# ESP32-S31 register map
Vendor: ESPRESSIF SYSTEMS (SHANGHAI) CO., LTD.; Series: ESP32 S-Series; File version: 1
CPU: RV32IMAFC r0p0, little endian, no MPU, FPU, 0 interrupt priority bits
Address unit: 32 bits
Registers are 32-bit, read-write, reset 0x0 unless marked. A register's access mark holds for its fields unless they carry their own. Offsets are from the block's base; [hi:lo] are bit positions; {n}, {i} and the like mark numbered series.

## ECDSA — ECDSA (Elliptic Curve Digital Signature Algorithm) Accelerator
Base 0x2050E000
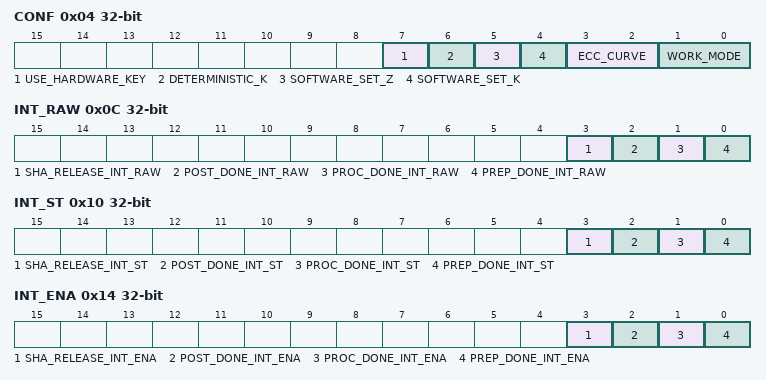
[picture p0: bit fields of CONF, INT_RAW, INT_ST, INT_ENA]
0x04 CONF — ECDSA configure register
  [7] USE_HARDWARE_KEY — Configures the ECDSA use software key or hardware key.\\ 0: Software key. \\ 1: Hardware key. \\
  [6] DETERMINISTIC_K — The source of hardware generated k. 0: k is generated by TRNG. 1: k is generated by deterministic derivation algorithm.
  [5] SOFTWARE_SET_Z — The source of z select bit. 0: z is generated from SHA result. 1: z is written by software.
  [4] SOFTWARE_SET_K — The source of k select bit. 0: k is automatically generated by hardware. 1: k is written by software.
  [3:2] ECC_CURVE — The ecc curve select bit of ECDSA Accelerator. 0: P-192. 1: P-256. 2: P-384 3: SM2.
  [1:0] WORK_MODE — The work mode bits of ECDSA Accelerator. 0: Signature Verify Mode. 1: Signature Generate Mode. 2: Export Public Key Mode. 3: invalid.
0x08 CLK — ECDSA clock gate register
  [0] GATE_FORCE_ON — Write 1 to force on register clock gate.
0x0C INT_RAW ro — ECDSA interrupt raw register, valid in level.
  [3] SHA_RELEASE_INT_RAW — The raw interrupt status bit for the ecdsa_sha_release_int interrupt
  [2] POST_DONE_INT_RAW — The raw interrupt status bit for the ecdsa_post_done_int interrupt
  [1] PROC_DONE_INT_RAW — The raw interrupt status bit for the ecdsa_proc_done_int interrupt
  [0] PREP_DONE_INT_RAW — The raw interrupt status bit for the ecdsa_prep_done_int interrupt
0x10 INT_ST ro — ECDSA interrupt status register.
  [3] SHA_RELEASE_INT_ST — The masked interrupt status bit for the ecdsa_sha_release_int interrupt
  [2] POST_DONE_INT_ST — The masked interrupt status bit for the ecdsa_post_done_int interrupt
  [1] PROC_DONE_INT_ST — The masked interrupt status bit for the ecdsa_proc_done_int interrupt
  [0] PREP_DONE_INT_ST — The masked interrupt status bit for the ecdsa_prep_done_int interrupt
0x14 INT_ENA — ECDSA interrupt enable register.
  [3] SHA_RELEASE_INT_ENA — The interrupt enable bit for the ecdsa_sha_release_int interrupt
  [2] POST_DONE_INT_ENA — The interrupt enable bit for the ecdsa_post_done_int interrupt
  [1] PROC_DONE_INT_ENA — The interrupt enable bit for the ecdsa_proc_done_int interrupt
  [0] PREP_DONE_INT_ENA — The interrupt enable bit for the ecdsa_prep_done_int interrupt
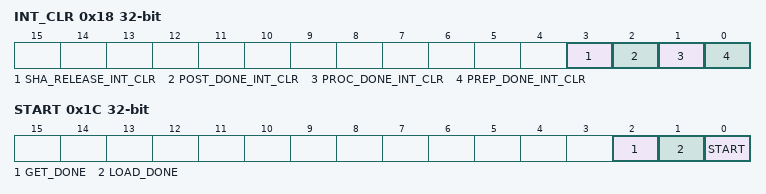
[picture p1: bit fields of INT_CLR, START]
0x18 INT_CLR wo — ECDSA interrupt clear register.
  [3] SHA_RELEASE_INT_CLR — Set this bit to clear the ecdsa_sha_release_int interrupt
  [2] POST_DONE_INT_CLR — Set this bit to clear the ecdsa_post_done_int interrupt
  [1] PROC_DONE_INT_CLR — Set this bit to clear the ecdsa_proc_done_int interrupt
  [0] PREP_DONE_INT_CLR — Set this bit to clear the ecdsa_prep_done_int interrupt
0x1C START wo — ECDSA start register
  [2] GET_DONE — Write 1 to input get done signal of ECDSA Accelerator. This bit will be self-cleared after configuration.
  [1] LOAD_DONE — Write 1 to input load done signal of ECDSA Accelerator. This bit will be self-cleared after configuration.
  [0] START — Write 1 to start caculation of ECDSA Accelerator. This bit will be self-cleared after configuration.
0x20 STATE ro — ECDSA status register
  [1:0] BUSY — The status bits of ECDSA Accelerator. ECDSA is at 0: IDLE, 1: LOAD, 2: GET, 3: BUSY state.
0x24 RESULT ro — ECDSA result register
  [0] OPERATION_RESULT — The operation result bit of ECDSA Accelerator, only valid when ECDSA calculation is done.
0x28 TIMEOUT_LIMIT reset 0xFFFFFFFF — ECDSA timeout limit configurate register
  [31:0] TIMEOUT_LIMIT — The timeout limitation for waiting sub-IP.
0x2C FREE reset 0x1 — ECDSA free state
  [0] FREE — Represents if ECDSA Accelerator is free or not. \\ 0: non-free\\ 1: free\\
{0x40+4i} KEY_{i} (i=0..11) — ECDSA key data register {i}
  [31:0] KEY_{i} — These bits stores key_{i} that is a part of key material.
0xFC DATE reset 0x2508190 — Version control register
  [27:0] DATE — ECDSA version control register
0x200 SHA_MODE — ECDSA control SHA register
  [3:0] SHA_MODE — The work mode bits of SHA Calculator in ECDSA Accelerator. 0: SHA1. 1: SHA-224. 2: SHA-256. 3: SHA-384 4: SHA-512. 5: SHA-512224. 6: SHA-512256. 14:SM3. Others: invalid.
0x210 SHA_START wo — ECDSA control SHA register
  [0] SHA_START — Write 1 to start the first caculation of SHA Calculator in ECDSA Accelerator. This bit will be self-cleared after configuration.
0x214 SHA_CONTINUE wo — ECDSA control SHA register
  [0] SHA_CONTINUE — Write 1 to start the latter caculation of SHA Calculator in ECDSA Accelerator. This bit will be self-cleared after configuration.
0x218 SHA_BUSY ro — ECDSA status register
  [0] SHA_BUSY — The busy status bit of SHA Calculator in ECDSA Accelerator. 1:SHA is in calculation. 0: SHA is idle.
{0x280+i} MESSAGE_MEM[{i}] (i=0..63) 8-bit access not given — The memory that stores message.
{0x3E0+i} R_MEM[{i}] (i=0..47) 8-bit access not given — The memory that stores r.
{0x410+i} S_MEM[{i}] (i=0..47) 8-bit access not given — The memory that stores s.
{0x440+i} Z_MEM[{i}] (i=0..47) 8-bit access not given — The memory that stores software written z.
{0x470+i} QAX_MEM[{i}] (i=0..47) 8-bit access not given — The memory that stores x coordinates of QA or software written k.
{0x4A0+i} QAY_MEM[{i}] (i=0..47) 8-bit access not given — The memory that stores y coordinates of QA.
